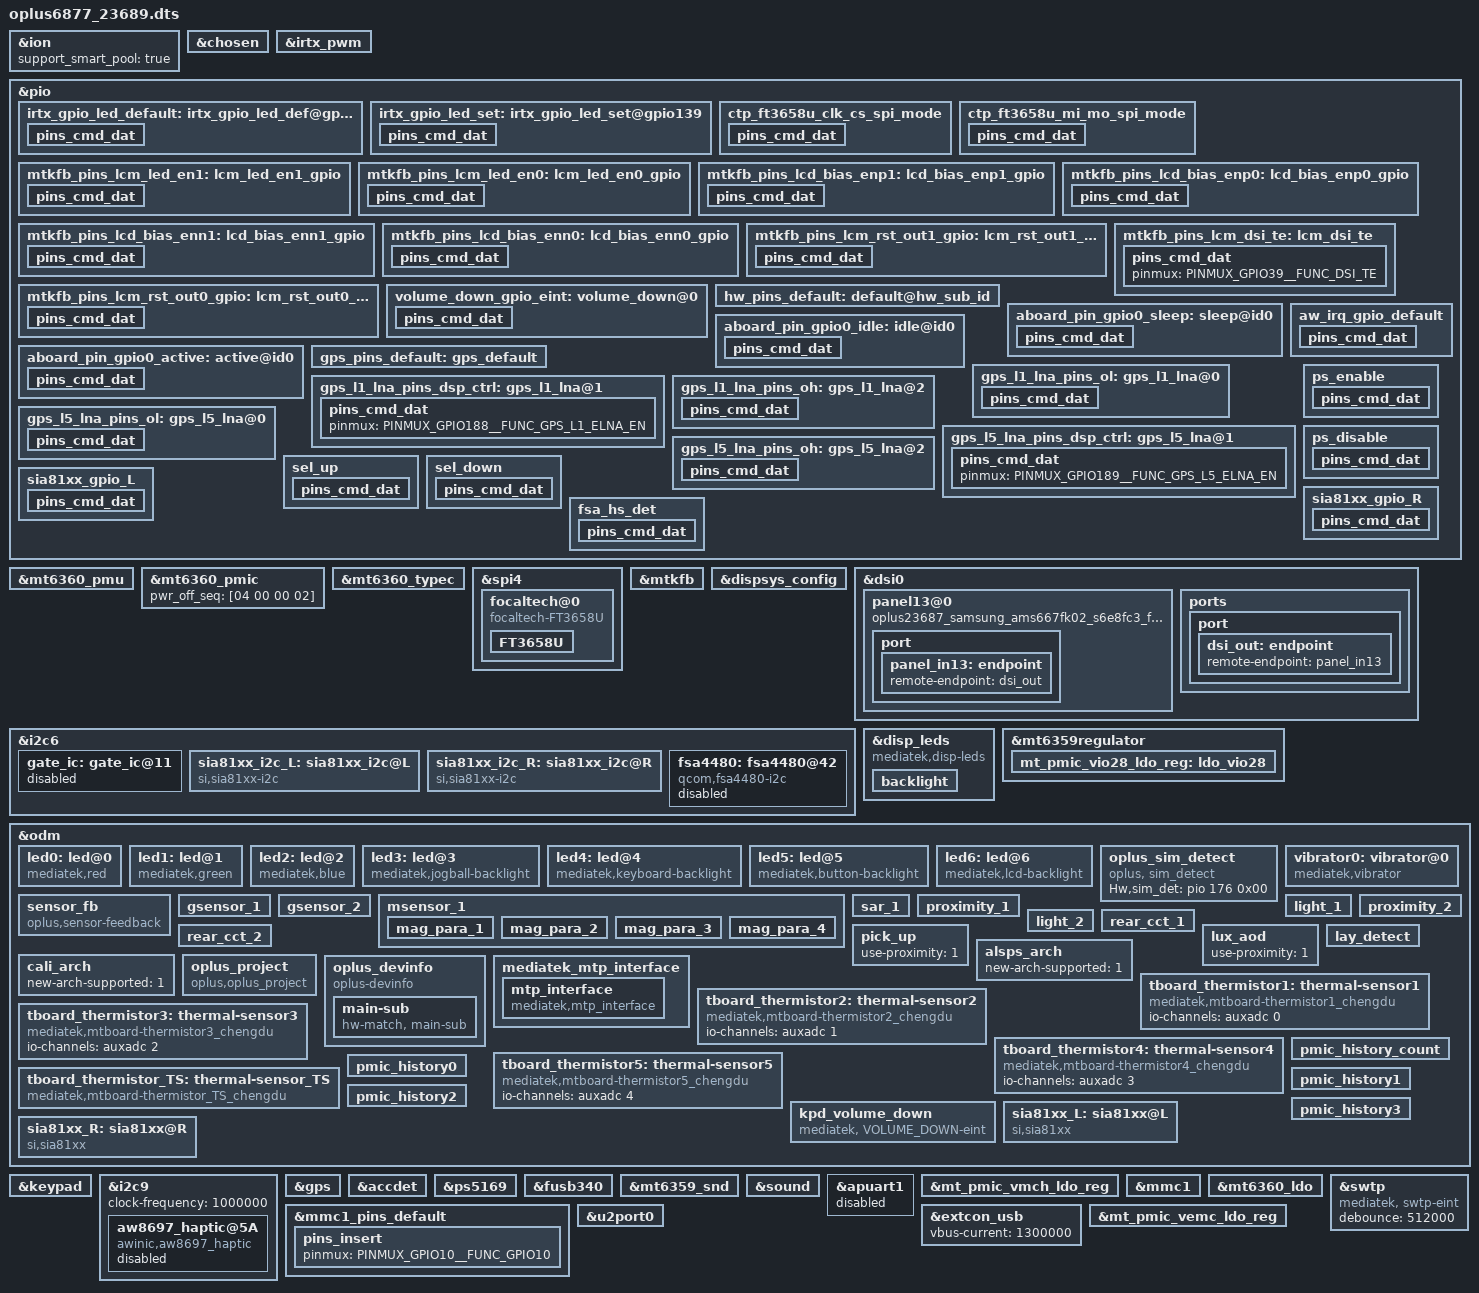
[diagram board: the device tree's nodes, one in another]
/*
 * Mediatek's mt6853 SoC device tree source
 *
 * Copyright (C) 2016 MediaTek Inc.
 *
 * This program is free software; you can redistribute it and/or modify
 * it under the terms of the GNU General Public License version 2 as
 * published by the Free Software Foundation.
 *
 * This program is distributed in the hope that it will be useful,
 * but WITHOUT ANY WARRANTY; without even the implied warranty of
 * MERCHANTABILITY or FITNESS FOR A PARTICULAR PURPOSE.
 * See http://www.gnu.org/licenses/gpl-2.0.html for more details.
 */
/dts-v1/;
/plugin/;
#include <dt-bindings/interrupt-controller/irq.h>
#include <dt-bindings/interrupt-controller/arm-gic.h>
#include <dt-bindings/pinctrl/mt6877-pinfunc.h>

/* #ifdef CONFIG_UFF_FINGERPRINT */
#include "mediatek/oplus_uff_23689.dtsi"
/* #endif CONFIG_UFF_FINGERPRINT */

&ion {
	support_smart_pool = "true";
};

/* chosen */
&chosen {
	atag,videolfb-fb_base_l = <0x7e605000>;
	atag,videolfb-fb_base_h = <0x0>;
	atag,videolfb-islcmfound = <1>;
	atag,videolfb-islcm_inited = <0>;
	atag,videolfb-fps= <6000>;
	atag,videolfb-vramSize= <0x1be0000>;
	atag,videolfb-lcmname=
		"td4330_fhdp_dsi_cmd_auo_rt4831_drv";
};

/* IRTX GPIO Start */
&irtx_pwm {
	pinctrl-names = "irtx_gpio_led_default", "irtx_gpio_led_set";
	pinctrl-0 = <&irtx_gpio_led_default>;
	pinctrl-1 = <&irtx_gpio_led_set>;
	status = "okay";
};
&pio {
	/* IRTX GPIO Settings -Start */
	/* default: GPIO0, output, high */
	irtx_gpio_led_default:irtx_gpio_led_def@gpio139 {
		pins_cmd_dat {
			pinmux = <PINMUX_GPIO139__FUNC_GPIO139>;
			slew-rate = <1>;
			bias-disable;
			output-low;
			input-schmitt-enable = <0>;
		};
	};

	irtx_gpio_led_set:irtx_gpio_led_set@gpio139 {
		pins_cmd_dat {
			pinmux = <PINMUX_GPIO139__FUNC_PWM_1>;
			slew-rate = <1>;
			output-high;
		};
	};
}; /* IRTX GPIO Settings -End */

&mt6360_pmu {
	mt6360,intr_gpio_num = <4>; /* direct defined GPIO num */
	mt6360,intr_gpio = <&pio 4 0x0>;
};

&mt6360_pmic {
	pwr_off_seq = [04 00 00 02];
};

&mt6360_typec {
	mt6360pd,intr_gpio_num = <5>; /* direct defined GPIO num */
	mt6360pd,intr_gpio = <&pio 5 0x0>;
};

&spi4 {
	status = "okay";
	#address-cells = <1>;
	#size-cells = <0>;

	pinctrl-names = "default";
	pinctrl-0 = <&ctp_ft3658u_clk_cs_spi_mode>, <&ctp_ft3658u_mi_mo_spi_mode>;
	focaltech@0{
		compatible = "focaltech-FT3658U";
		reg = <0x0>;
		chip-name = "FT3658U";
		status = "okay";
		spi-max-frequency = <6000000>;
		/* Interrupt && Irq-gpio */
		interrupt-parent = <&pio>;
		interrupts = <14 0x2002>;

		/* Power Config */

		vdd_2v8-supply  = <&mt_pmic_vtp_ldo_reg>;
		vdd_2v8_volt = <3000000>;



		/* Other HW Resource */

		irq-gpio = <&pio 14 0x2002>;
		reset-gpio = <&pio 15 0x1>;

		touchpanel,max-num-support = <10>;
		touchpanel,tx-rx-num = <16 34>;
		earsense,tx-rx-num = <17 18>;
		touchpanel,panel-coords = <8640 19200>;
		touchpanel,display-coords = <1080 2400>;
		touchpanel,touchmajor-limit = <128 216>;
		touchpanel,elimination-range = <20 200 200>;
		//touchpanel,int-mode = <1>; /*0: interrupt and disable, 1:interrupt and not disable*/
		touchpanel,msecs-to-jiffies-time = <150>;
		touchpanel,smooth-level = <0 110 115 120 140 155>;
		touchpanel,smooth-level-charging = <0 110 115 120 140 155>;
		touchpanel,sensitive-level = <0 19 16 14 13 10>;
		touchpanel,tp-index = <0>;
		touchpanel,high-frame-rate-time = <60>;

		vid_len = <2>;
		//firmware_name = "0xAB30500";
		tp_type = <8>; /* panel-SAMSUNG*/
		platform_support_project = <23613 23686 23687 23689 23707 23709>;
		platform_support_project_dir = <23687 23687 23687 23687 23687 23687>;
		platform_support_project_commandline = "default_commandline","default_commandline","default_commandline","default_commandline","default_commandline","default_commandline";

		prevention,curved_screen_V2;
		prevention,grip_disable_level = <6>;
		prevention,updelay_time_ms = <30>;
		prevention,makeup_cnt_weight = <4 1 2 2 2>;
		prevention,large_corner_range = <960 2360>;
		prevention,large_corner_judge_condition = <500 300 900 6 6>;
		prevention,trx_reject_condition = <8 7 7>;
		prevention,trx_strict_reject_condition = <7 6 6>;
		prevention,large_judge_time_ms = <500 50 30>;
		prevention,large_exit_condition = <15 12 2>;
		prevention,single_channel_width = <240 240>;
		prevention,normal_tap_condition = <10 300>;
		prevention,long_edge_condition = <230 100 180 80>;
		prevention,long_strict_edge_condition = <170 80>;
		prevention,long_fingerhold_condition = <50 6 4 4>;
		prevention,short_edge_condition = <230 100 180 80>;
		prevention,short_strict_edge_condition = <160 60>;
		prevention,large_strict_exit_condition = <5 5>;
		prevention,top_corner_config = <420 1194 360>;
		prevention,edge_swipe_config = <240 896>;

		prevention,curved_screen_V4;
		prevention,long_eliminate_point_type = <2 8640 6400 210 19200 300 1>;
		prevention,long_fingerhold_condition2 = <555 1194 0 0>;
		prevention,top_corner_config2 =<3 80 630 895 0>;
		prevention,hor_long_top_corner_config =<228 1573 0 0>;
		prevention,top_middle_config =<8640 790 790 0>;
		prevention,corner_eliminate_point_type =<0 960 1573 1>;
		prevention,finger_hold_differ_size = <1 0 240 240>;
		prevention,finger_hold_max_rx_exit_distance = <5 240 1600>;
		prevention,max_rx_exit_distance = <1 5 150 240 1600>;
		prevention,dynamic_finger_hold_exit_distance = <1 240 1600 280>;
		prevention,edge_sliding_matched_support = <1 220 3 0>;

		//grip v4.2 reclining mode
		prevention,reclining_mode_support = <1>;
		prevention,long_eliminate_point_type_recli = <2 8640 6400 210 19200 300 1>;
		prevention,finger_hold_differ_size_recli = <1 0 240 240>;
		prevention,finger_hold_max_rx_exit_distance_recli = <5 240 1600>;
		prevention,max_rx_exit_distance_recli = <1 5 150 240 1600>;
		prevention,dynamic_finger_hold_exit_distance_recli = <1 240 1600 280>;
		prevention,edge_sliding_matched_support_recli = <1 220 3 0>;
		/* SW Support Feature Control */
		//esd_handle_support;
		//register-is-16bit;
		//wireless_charger_support;
		headset_pump_support;
		fw_edge_limit_support;

		health_monitor_v2_support;
		black_gesture_support;
		charger_pump_support;
		//lcd_tp_refresh_support;
		fw_update_app_support;
		smart_gesture_support;
		game_switch_support;
		report_flow_unlock_support;
		kernel_grip_support;
		fingerprint_underscreen_support;
		pressure_report_support;
		touchpanel,single-optimized-time = <8>;
		auto_test_force_pass_support;
		snr_read_support;
		high_resolution_support;
		algorithm_support;
		screenoff_fingerprint_info_support;
		irq_need_dev_resume_ok;
		sportify_aod_gesture_support;
		black_gesture_indep_support;
		thermal_detect_support;
		exception_upload_support;
		palm_to_sleep_support;

		/*
		 *Virtual Key Config:
		 *1:touchpanel,button-type: <virtualkey_type  supportted_button-map>
		 *virtualkey_type:
		 *Type 1: using board_properties
		 *Type 2: using same IC (button zone&& touch zone are seprate)
		 *Type 3: using diffrent IC (button zone&& touch zone are seprate)
		 *Type 4: No need of virtual key process
		 *supportted_button-map:select|menu|home|back
		 *
		 *2:touchpanel,button-map
		 *type (X1,Y1)(X2,Y2)(X3,Y3)(Width_X,Hight_Y)--Only when button-type is 0
		 */
		touchpanel,button-type = <4>;
		touchpanel.button-TRx = <0 0>;

		FT3658U {
			switch_report_rate;
			report_rate_default = <60>;
			report_rate_game_value = <0x02>;
		};
	};
};

&pio {
	ctp_ft3658u_clk_cs_spi_mode: ctp_ft3658u_clk_cs_spi_mode{
		pins_cmd_dat {
			pinmux = <PINMUX_GPIO64__FUNC_SPI4_CLK>,
				<PINMUX_GPIO65__FUNC_SPI4_CSB>;
			mediatek,drive-strength-adv = <0>;/*EH[2:0]*/
			drive-strength = <2>;
		};
	};
	ctp_ft3658u_mi_mo_spi_mode: ctp_ft3658u_mi_mo_spi_mode {
		pins_cmd_dat {
			pinmux = <PINMUX_GPIO12__FUNC_SPI4_MI>,
				<PINMUX_GPIO13__FUNC_SPI4_MO>;
			drive-strength = <2>;
		};
	};

};
/*touch end*/

&pio {
	mtkfb_pins_lcm_led_en1: lcm_led_en1_gpio {
		pins_cmd_dat {
			pinmux = <PINMUX_GPIO107__FUNC_GPIO107>;
			slew-rate = <1>;
			output-high;
		};
	};

	mtkfb_pins_lcm_led_en0: lcm_led_en0_gpio {
		pins_cmd_dat {
			pinmux = <PINMUX_GPIO107__FUNC_GPIO107>;
			slew-rate = <1>;
			output-low;
		};
	};

	mtkfb_pins_lcd_bias_enp1: lcd_bias_enp1_gpio {
		pins_cmd_dat {
			pinmux = <PINMUX_GPIO108__FUNC_GPIO108>;
			slew-rate = <1>;
			output-high;
		};
	};

	mtkfb_pins_lcd_bias_enp0: lcd_bias_enp0_gpio {
		pins_cmd_dat {
			pinmux = <PINMUX_GPIO108__FUNC_GPIO108>;
			slew-rate = <1>;
			output-low;
		};
	};

	mtkfb_pins_lcd_bias_enn1: lcd_bias_enn1_gpio {
		pins_cmd_dat {
			pinmux = <PINMUX_GPIO111__FUNC_GPIO111>;
			slew-rate = <1>;
			output-high;
		};
	};

	mtkfb_pins_lcd_bias_enn0: lcd_bias_enn0_gpio {
		pins_cmd_dat {
			pinmux = <PINMUX_GPIO111__FUNC_GPIO111>;
			slew-rate = <1>;
			output-low;
		};
	};

	mtkfb_pins_lcm_rst_out1_gpio: lcm_rst_out1_gpio {
		pins_cmd_dat {
			pinmux = <PINMUX_GPIO40__FUNC_GPIO40>;
			slew-rate = <1>;
			output-high;
		};
	};

	mtkfb_pins_lcm_rst_out0_gpio: lcm_rst_out0_gpio {
		pins_cmd_dat {
			pinmux = <PINMUX_GPIO40__FUNC_GPIO40>;
			slew-rate = <1>;
			output-low;
		};
	};
	mtkfb_pins_lcm_dsi_te: lcm_dsi_te {
		pins_cmd_dat {
			pinmux = <PINMUX_GPIO39__FUNC_DSI_TE>;
		};
	};
};

&mtkfb {
	pinctrl-names = "lcm_led_en1_gpio", "lcm_led_en0_gpio",
		"lcd_bias_enp1_gpio", "lcd_bias_enp0_gpio",
		"lcd_bias_enn1_gpio", "lcd_bias_enn0_gpio",
		"lcm_rst_out1_gpio", "lcm_rst_out0_gpio",
		"mode_te_te";
	pinctrl-0 = <&mtkfb_pins_lcm_led_en1>;
	pinctrl-1 = <&mtkfb_pins_lcm_led_en0>;
	pinctrl-2 = <&mtkfb_pins_lcd_bias_enp1>;
	pinctrl-3 = <&mtkfb_pins_lcd_bias_enp0>;
	pinctrl-4 = <&mtkfb_pins_lcd_bias_enn1>;
	pinctrl-5 = <&mtkfb_pins_lcd_bias_enn0>;
	pinctrl-6 = <&mtkfb_pins_lcm_rst_out1_gpio>;
	pinctrl-7 = <&mtkfb_pins_lcm_rst_out0_gpio>;
	pinctrl-8 = <&mtkfb_pins_lcm_dsi_te>;
	status = "okay";
};
&dispsys_config {
	pinctrl-names =
		"lcm_rst_out1_gpio", "lcm_rst_out0_gpio",
		"mode_te_te";
	pinctrl-0 = <&mtkfb_pins_lcm_rst_out1_gpio>;
	pinctrl-1 = <&mtkfb_pins_lcm_rst_out0_gpio>;
	pinctrl-2 = <&mtkfb_pins_lcm_dsi_te>;
	status = "okay";

	helper-value = <0>, /*MTK_DRM_OPT_STAGE*/
		<1>, /*MTK_DRM_OPT_USE_CMDQ*/
		<1>, /*MTK_DRM_OPT_USE_M4U*/
		<0>, /*MTK_DRM_OPT_SODI_SUPPORT*/
		<1>, /*MTK_DRM_OPT_IDLE_MGR*/
		<0>, /*MTK_DRM_OPT_IDLEMGR_SWTCH_DECOUPLE*/
		<0>, /*MTK_DRM_OPT_IDLEMGR_BY_REPAINT*/
		<0>, /*MTK_DRM_OPT_IDLEMGR_ENTER_ULPS*/
		<0>, /*MTK_DRM_OPT_IDLEMGR_KEEP_LP11*/
		<0>, /*MTK_DRM_OPT_DYNAMIC_RDMA_GOLDEN_SETTING*/
		<1>, /*MTK_DRM_OPT_IDLEMGR_DISABLE_ROUTINE_IRQ*/
		<0>, /*MTK_DRM_OPT_MET_LOG*/
		<1>, /*MTK_DRM_OPT_USE_PQ*/
		<1>, /*MTK_DRM_OPT_ESD_CHECK_RECOVERY*/
		<1>, /*MTK_DRM_OPT_ESD_CHECK_SWITCH*/
		<1>, /*MTK_DRM_OPT_PRESENT_FENCE*/
		<1>, /*MTK_DRM_OPT_RDMA_UNDERFLOW_AEE*/
		<1>, /*MTK_DRM_OPT_DSI_UNDERRUN_AEE*/
		<1>, /*MTK_DRM_OPT_HRT*/
		<1>, /*MTK_DRM_OPT_HRT_MODE*/
		<0>, /*MTK_DRM_OPT_DELAYED_TRIGGER*/
		<1>, /*MTK_DRM_OPT_OVL_EXT_LAYER*/
		<0>, /*MTK_DRM_OPT_AOD*/
		<1>, /*MTK_DRM_OPT_RPO*/
		<0>, /*MTK_DRM_OPT_DUAL_PIPE*/
		<0>, /*MTK_DRM_OPT_DC_BY_HRT*/
		<0>, /*MTK_DRM_OPT_OVL_WCG*/
		<0>, /*MTK_DRM_OPT_OVL_SBCH*/
		<1>, /*MTK_DRM_OPT_COMMIT_NO_WAIT_VBLANK*/
		<0>, /*MTK_DRM_OPT_MET*/
		<0>, /*MTK_DRM_OPT_REG_PARSER_RAW_DUMP*/
		<0>, /*MTK_DRM_OPT_VP_PQ*/
		<0>, /*MTK_DRM_OPT_GAME_PQ*/
		<0>, /*MTK_DRM_OPT_MMPATH*/
		<1>, /*MTK_DRM_OPT_HBM*/
		<0>, /*MTK_DRM_OPT_VDS_PATH_SWITCH*/
		<0>, /*MTK_DRM_OPT_LAYER_REC*/
		<0>, /*MTK_DRM_OPT_CLEAR_LAYER*/
		<1>, /*MTK_DRM_OPT_LFR*/
		<1>; /*MTK_DRM_OPT_DYN_MIPI_CHANGE*/
};

&dsi0 {
	status = "okay";
	#address-cells = <1>;
	#size-cells = <0>;
	panel13@0 {
		compatible = "oplus23687_samsung_ams667fk02_s6e8fc3_fhdp_dsi_vdo";
		reg = <0>;
		vddr-enable-gpios = <&pio 107 0>;
		vci-enable-gpios = <&pio 105 0>;
		reset-gpios = <&pio 40 0>;
		pinctrl-names = "default";
		port {
			panel_in13: endpoint {
				remote-endpoint = <&dsi_out>;
			};
		};
	};
	ports {
		port {
			dsi_out: endpoint {
				remote-endpoint = <&panel_in13>;
			};
		};
	};
};

&i2c6 {
	gate_ic: gate_ic@11 {
		status = "disable";
	};
};

&disp_leds {
	compatible = "mediatek,disp-leds";
	backlight {
		label = "lcd-backlight";
		max-brightness = <4095>;
		led-bits = <12>;
		trans-bits = <12>;
		// support_silky_brightness = <1>;
		default-state = "on";
	};
};

&mt6359regulator {
	mt_pmic_vio28_ldo_reg: ldo_vio28 {
		regulator-name = "vio28";
		regulator-min-microvolt = <3300000>;
		regulator-max-microvolt = <3300000>;
		regulator-enable-ramp-delay = <1920>;
		};
};

&odm {
	led0:led@0 {
		compatible = "mediatek,red";
		led_mode = <0>;
		data = <1>;
		pwm_config = <0 0 0 0 0>;
	};
	led1:led@1 {
		compatible = "mediatek,green";
		led_mode = <0>;
		data = <1>;
		pwm_config = <0 0 0 0 0>;
	};
	led2:led@2 {
		compatible = "mediatek,blue";
		led_mode = <0>;
		data = <1>;
		pwm_config = <0 0 0 0 0>;
	};
	led3:led@3 {
		compatible = "mediatek,jogball-backlight";
		led_mode = <0>;
		data = <1>;
		pwm_config = <0 0 0 0 0>;
	};
	led4:led@4 {
		compatible = "mediatek,keyboard-backlight";
		led_mode = <0>;
		data = <1>;
		pwm_config = <0 0 0 0 0>;
	};
	led5:led@5 {
		compatible = "mediatek,button-backlight";
		led_mode = <0>;
		data = <1>;
		pwm_config = <0 0 0 0 0>;
	};
	led6:led@6 {
		compatible = "mediatek,lcd-backlight";
		led_mode = <4>;
		data = <1>;
		pwm_config = <0 1 0 0 0>;
	};
    oplus_sim_detect {
	    compatible = "oplus, sim_detect";
	    Hw,sim_det = <&pio 176 0x00>;
    };
    vibrator0:vibrator@0 {
	    compatible = "mediatek,vibrator";
	    vib_timer = <35>;
	    vib_limit = <9>;
	    vib_vol= <9>;
    };
/* sensor start */
	/*
	enum {
		LIS3DH,
		LSM6DS3,
		BMI160,
		LIS2HH12,
		LSM6DSM,
		BMI2XY,
		LSM6DSO,
		BMA4XY,
		SC7A20,
		ICM4X6XX,
	};
	*/
    sensor_fb: sensor_fb {
            compatible = "oplus,sensor-feedback";
    };

	gsensor_1: gsensor_1 {
		status = "okay";
		sensor_name = <7>;//ICM4X6XX
		device_name = "icm4x6xx";
		i2c_num = <2>;
		i2c_addr = <0>;
		direction = <2>;
		eint_num = <1>;
		step_count_7_en = <1>;
		config_miso = <1>;
		correct_y_bias = <1>;
		gyro_cali_version= <2>;
		gyro_cali_range = <350>; //0.35 rad/s
		acc_cali_range= <300 300 300>; //250mg
	};
	gsensor_2: gsensor_2 {
		status = "okay";
		sensor_name = <10>;//BMI3XY
		device_name = "bmi3xy";
		i2c_num = <2>;
		i2c_addr = <0>;
		direction = <1>;
		eint_num = <1>;
		gyro_cali_version= <2>;
		gyro_cali_range = <350>; //0.35 rad/s
		acc_cali_range= <300 300 300>; //250mg
	};
	/*
	enum {
		AKM09911,
		MMC3530,
		MMC5603,
		MXG4300,
	};
	*/
	msensor_1: msensor_1 {
		status = "okay";
		sensor_name = <2>;//MMC5603
		i2c_num = <0>;
		i2c_addr = <48>;
		direction = <3>;
		eint_num = <0>;
		para_num = <4>;
		libname = "mmc";
		mag_para_1 {
			match_projects = <23613>;
			soft-mag-parameter = <9969 0 755 0 36 0 157 1 8220 0 124 0 449 0 24 0 10391 0>;
		};
		mag_para_2 {
			match_projects = <23686>;
			soft-mag-parameter = <9995 0 224 0 119 1 686 1 8070 0 198 0 175 0 387 0 10181 0>;
		};
		mag_para_3 {
			match_projects = <23687>;
			soft-mag-parameter = <9959 0 875 0 186 0 269 1 8184 0 257 0 89 0 120 0 10452 0>;
		};
		mag_para_4 {
			match_projects = <23689>;
			soft-mag-parameter = <9997 0 12 1 228 0 806 0 9125 0 82 0 196 1 333 0 10375 0>;
		};
	};
	/*
	enum {
		SX933x
	};
	*/
	sar_1: sar_1 {
		status = "okay";
		sensor_name = <0>;//SX933x
		i2c_num = <0>;
		i2c_addr = <40>;
		direction = <4>;
		eint_num = <13>;
		channel_num = <2>;
		channel_0_min = <0>;
		channel_0_max = <70000>;
		channel_1_min = <0>;
		channel_1_max = <70000>;
		channel_2_min = <0>;
		channel_2_max = <70000>;
		channel_3_min = <0>;
		channel_3_max = <70000>;
		reg_table_num = <3>;
	};
	/*
	enum {
		TMD2725,
		APSD9922,
		STK3335,
		STK3331,
		STK2232,
		TCS3701,
		STK32600,
	};
	*/
	proximity_1: proximity_1 {
		status = "okay";
		sensor_name = <6>;//STK32600
		i2c_num = <0>;
		i2c_addr = <72>;
		direction = <4>;
		eint_num = <2>;
		low_step = <300>;
		high_step = <400>;
		low_limit = <400>;
		high_limit = <600>;
		dirty_low_step = <300>;
		dirty_high_step = <400>;
		ps_dirty_limit = <1800>;
		ps_ir_limit = <2000>;
		ps_adjust_min = <0>;
		ps_adjust_max = <1850>;
		sampling_count = <5>;
		step_max = <400>;
		step_min = <100>;
		step_div = <2000>;
		anti_shake_delta = <70>;
		dynamic_cali_max = <5000>;
		raw2offset_radio = <1000>;
		offset_max = <60000>;
		offset_range_min = <0>;
		offset_range_max = <65535>;
		force_cali_limit = <2000>;
		cali_jitter_limit = <30>;
		cal_offset_margin = <3000>;
		sensor-reg = <0x03 0x28>;
		is_use_force_cali = <1>;
	};
	light_1: light_1 {
		status = "okay";
		sensor_name = <6>;//STK32600
		i2c_num = <0>;
		i2c_addr = <72>;
		direction = <4>;
		eint_num = <2>;
		als_buffer_length =<8>;
		als_ratio = <110>;
		als_type = <2>;//<1-normal;2-under screen;3-normal needed compensation>
		device_name = "stk32600";
		use_als_c2 = <1>;
	};
	proximity_2: proximity_2 {
		status = "okay";
		sensor_name = <10>;//STK33C01
		device_name = "stk33c01";
		i2c_num = <0>;
		i2c_addr = <72>;
		direction = <4>;
		eint_num = <2>;
		low_step = <300>;
		high_step = <400>;
		low_limit = <400>;
		high_limit = <600>;
		dirty_low_step = <300>;
		dirty_high_step = <400>;
		ps_dirty_limit = <1800>;
		ps_ir_limit = <2000>;
		ps_adjust_min = <0>;
		ps_adjust_max = <1850>;
		sampling_count = <5>;
		step_max = <400>;
		step_min = <100>;
		step_div = <2000>;
		anti_shake_delta = <70>;
		dynamic_cali_max = <5000>;
		raw2offset_radio = <1000>;
		offset_max = <60000>;
		offset_range_min = <0>;
		offset_range_max = <65534>;
		force_cali_limit = <2000>;
		cali_jitter_limit = <30>;
		cal_offset_margin = <3000>;
		is_use_force_cali = <1>;
		parameter-number = <8>;
		sensor-reg = <0x01 0x44
				0x03 0x28
				0x05 0x3F
				0xDB 0x00>; //override special reg
	};
	light_2: light_2 {
		status = "okay";
		sensor_name = <10>;//STK33C01
		i2c_num = <0>;
		i2c_addr = <72>;
		direction = <4>;
		eint_num = <2>;
		als_buffer_length =<8>;
		als_ratio = <110>;
		als_coef_ratio = <88>;
		als_type = <2>;//<1-normal;2-under screen;3-normal needed compensation>
		device_name = "stk33c01";

	};
	/*
	enum {
		STK37600,
		MN29005,
		TCS3408,
	};
	*/
	rear_cct_1: rear_cct_1 {
		status = "okay";
		sensor_name = <0>;//STK37600
		i2c_num = <1>;
		i2c_addr = <0x48>;
		direction = <0>;
		eint_num = <10>;
		available_sensor = <7>; // bit 0: rear als, bit 1: rear cct, bit 2: rear flicker
		gold_rear_cct_3k = <11083 14060 1700 488 64 42136>; // 3000k gold parameter
		gold_rear_cct_6k = <8488 13068 3928 372 64 42964>;  // 3000k gold parameter
		device_name = "stk37600";
		cct_coef_Lir = <9116000 0 259000 0 1711000 1 7351000 0 12875000 0
				1686000 0 3545000 0 6606000 0 51505000 0 3221000 1
				2492000 1 2826000 1>;
		cct_coef_Hir = <178000 1 14775000 1 36798000 1 13552000 0 24758000 0
				31340000 0 3274000 1 7368000 1 19817000 0 161000 1
				23000 0 392000 0>;
	};
	rear_cct_2: rear_cct_2 {
		status = "okay";
		sensor_name = <3>;//SIP1221LR1N
		i2c_num = <1>;
		i2c_addr = <0x59>;
		direction = <0>;
		eint_num = <10>;
		available_sensor = <4>; // bit 0: rear als, bit 1: rear cct, bit 2: rear flicker
		device_name = "sip1221lr1n";
	};
	pick_up: pick_up {
		status = "okay";
		use-proximity = <1>;
	};
	lux_aod: lux_aod {
		status = "okay";
		use-proximity = <1>;
	};
	alsps_arch: alsps_arch {
		status = "okay";
		new-arch-supported = <1>;
	};
	cali_arch: cali_arch {
		status = "okay";
		new-arch-supported = <1>;
	};
	lay_detect: lay_detect{
		status = "okay";
		max_angel = <90>;
		min_angel = <30>;
		lay_in_time = <10>;
		lay_out_time = <3>;
	};
/* sensor end */

/* OPLUS_BUG_STABILITY oplus project start */
	oplus_project:oplus_project {
		compatible = "oplus,oplus_project";
	};
	oplus_devinfo:oplus_devinfo {
		compatible = "oplus-devinfo";

		pinctrl-names = "default", "aboard_gpio0_sleep", "aboard_gpio0_active", "aboard_gpio0_idle";
		pinctrl-0 = <&hw_pins_default>;
		pinctrl-1 = <&aboard_pin_gpio0_sleep>;
		pinctrl-2 = <&aboard_pin_gpio0_active>;
		pinctrl-3 = <&aboard_pin_gpio0_idle>;
		main-sub {
			use_tristate_gpio;
            compatible = "hw-match, main-sub";
			aboard-gpio0 = <&pio 103 0x00>;
			aboard-patterns = <2 1 0 2>;
			/*main board*/
			match-projects = <23613 23686 23687 23689>;
        };
	};
/* OPLUS_BUG_STABILITY oplus project end */

	mediatek_mtp_interface:mediatek_mtp_interface {
		mtp_interface {
			compatible = "mediatek,mtp_interface";
			InterfaceClass = <255>;
			InterfaceSubClass = <255>;
			InterfaceProtocol = <0>;
	};
};


/*	tboard_thermistor5: thermal-sensor5 {
		compatible = "mediatek,mtboard-thermistor5";
		io-channels = <&auxadc 4>;
		io-channel-names = "thermistor-ch4";
	};
*/
/* 20221216, add for AP, 4G pA, 5G PA, charger, sub_bat, flashlight ntc*/
	tboard_thermistor1: thermal-sensor1 {
		compatible = "mediatek,mtboard-thermistor1_chengdu";
		io-channels = <&auxadc 0>;
		io-channel-names = "thermistor-ch0";
	};
	tboard_thermistor2: thermal-sensor2 {
		compatible = "mediatek,mtboard-thermistor2_chengdu";
		io-channels = <&auxadc 1>;
		io-channel-names = "thermistor-ch1";
	};
	tboard_thermistor3: thermal-sensor3 {
		compatible = "mediatek,mtboard-thermistor3_chengdu";
		io-channels = <&auxadc 2>;
		io-channel-names = "thermistor-ch2";
	};
	tboard_thermistor4: thermal-sensor4 {
		compatible = "mediatek,mtboard-thermistor4_chengdu";
		io-channels = <&auxadc 3>;
		io-channel-names = "thermistor-ch3";
	};
	tboard_thermistor5: thermal-sensor5 {
		compatible = "mediatek,mtboard-thermistor5_chengdu";
		io-channels = <&auxadc 4>;
		io-channel-names = "thermistor-ch4";
	};
	tboard_thermistor_TS: thermal-sensor_TS {
		compatible = "mediatek,mtboard-thermistor_TS_chengdu";
	};

	kpd_volume_down:kpd_volume_down {
		compatible = "mediatek, VOLUME_DOWN-eint";
		interrupt-parent = <&pio>;
		interrupts = <7 IRQ_TYPE_EDGE_FALLING 7 0>;
		debounce = <32000>;
		status = "okay";
	};

	pmic_history_count:pmic_history_count {
	};
	pmic_history0:pmic_history0 {
	};
	pmic_history1:pmic_history1 {
	};
	pmic_history2:pmic_history2 {
	};
	pmic_history3:pmic_history3 {
	};

};

&keypad {
	keypad,volume-down	= <&pio 7 0x00>;
	pinctrl-names = "volume_down_as_int";
	pinctrl-0 = <&volume_down_gpio_eint>;
	status = "okay";
};

&pio {
	volume_down_gpio_eint:volume_down@0{
		pins_cmd_dat {
			pinmux = <PINMUX_GPIO7__FUNC_GPIO7>;
			slew-rate = <0>;  /*direction 0:in, 1:out*/
			input-enable;
		};
	};
};

&pio {
        hw_pins_default:default@hw_sub_id {
        };

        aboard_pin_gpio0_sleep:sleep@id0 {
                pins_cmd_dat {
                        pinmux = <PINMUX_GPIO103__FUNC_GPIO103>;
                        slew-rate = <0>;
                        bias-pull-down;
                        input-enable;
                };
        };

        aboard_pin_gpio0_active:active@id0 {
                pins_cmd_dat {
                        pinmux = <PINMUX_GPIO103__FUNC_GPIO103>;
                        slew-rate = <0>;
                        bias-pull-up;
                        input-enable;
                };
        };

        aboard_pin_gpio0_idle:idle@id0 {
                pins_cmd_dat {
                        pinmux = <PINMUX_GPIO103__FUNC_GPIO103>;
                        slew-rate = <0>;
                        bias-disable;
                        input-enable;
                };
        };
};

&i2c9 {
    status = "okay";
	clock-frequency = <1000000>;

	/* AWINIC AW8697 Haptic */
	aw8697_haptic@5A {
		status = "disable";
		compatible = "awinic,aw8697_haptic";
		reg = <0x5A>;
		reset-gpio = <&pio 26 0x00>;
		irq-gpio = <&pio 30 0x00>;
		qcom,device_id = <815>;//aw86927
		audio_delay = <60>;
		qcom,aw86927_boost_voltage = /bits/ 8 <0x52>;

		pinctrl-names = "default";
		pinctrl-0 = <&aw_irq_gpio_default>;
	};
};

&pio{
	aw_irq_gpio_default: aw_irq_gpio_default {		//check
		pins_cmd_dat {
			pinmux = <PINMUX_GPIO30__FUNC_GPIO30>;
			input-enable;
			bias-pull-up = <MTK_PUPD_SET_R1R0_10>;
		};
	};

};

/* GPS GPIO standardization start */
&pio {
	gps_pins_default: gps_default {
	};
	gps_l1_lna_pins_ol: gps_l1_lna@0 {
		pins_cmd_dat {
			pinmux = <PINMUX_GPIO188__FUNC_GPIO188>;
			output-low;
		};
	};
	gps_l1_lna_pins_dsp_ctrl: gps_l1_lna@1 {
		pins_cmd_dat {
			pinmux = <PINMUX_GPIO188__FUNC_GPS_L1_ELNA_EN>;
		};
	};
	gps_l1_lna_pins_oh: gps_l1_lna@2 {
		pins_cmd_dat {
			pinmux = <PINMUX_GPIO188__FUNC_GPIO188>;
			output-high;
		};
	};
	gps_l5_lna_pins_ol: gps_l5_lna@0 {
		pins_cmd_dat {
			pinmux = <PINMUX_GPIO189__FUNC_GPIO189>;
			output-low;
		};
	};
	gps_l5_lna_pins_dsp_ctrl: gps_l5_lna@1 {
		pins_cmd_dat {
			pinmux = <PINMUX_GPIO189__FUNC_GPS_L5_ELNA_EN>;
		};
	};
	gps_l5_lna_pins_oh: gps_l5_lna@2 {
		pins_cmd_dat {
			pinmux = <PINMUX_GPIO189__FUNC_GPIO189>;
			output-high;
		};
	};
};
&gps {
	pinctrl-names = "default",
		"gps_l1_lna_disable",
		"gps_l1_lna_dsp_ctrl",
		"gps_l1_lna_enable";
		//"gps_l5_lna_disable",
		//"gps_l5_lna_dsp_ctrl",
		//"gps_l5_lna_enable";
	pinctrl-0 = <&gps_pins_default>;
	pinctrl-1 = <&gps_l1_lna_pins_ol>;
	pinctrl-2 = <&gps_l1_lna_pins_dsp_ctrl>;
	pinctrl-3 = <&gps_l1_lna_pins_oh>;
	//pinctrl-4 = <&gps_l5_lna_pins_ol>;
	//pinctrl-5 = <&gps_l5_lna_pins_dsp_ctrl>;
	//pinctrl-6 = <&gps_l5_lna_pins_oh>;
	status = "okay";
};
/* GPS GPIO standardization end */

&accdet {
	/* accdet micbias voltage: 0x09:2.85v 0x08:2.8v 0x07,
	 * 2.7v;0x05,2.5v;0x02,1.9v
	 */
	accdet-mic-vol = <7>;
	/* accdet pwm_width, pwm_thresh, fall_delay, rise_delay
	 * debounce0, debounce1, debounce3, debounce4
	 * eint pwm_width, eint pwm_thresh
	 * eint deb(debounce0, debounce1, debounce2, debounce3), inv_debounce
	 */
	//#ifdef OPLUS_ARCH_EXTENDS
	/* Modify for bug 136344 */
	headset-mode-setting = <0x500 0x500 1 0x1f0
				0x1325 0x800 0x3D4 0x44
				0x0 0x7
				0x5 0x9 0x9 0xd 0xe>;
	//#else /* OPLUS_ARCH_EXTENDS */
	/*headset-mode-setting = <0x500 0x500 1 0x1f0
	*                      0x800 0x800 0x20 0x44
	*                      0x4 0x1
	*                      0x5 0x3 0x3 0x5 0xe>;
	*/
	//#endif /* OPLUS_ARCH_EXTENDS */
	accdet-plugout-debounce = <1>;
	/*1:ACC mode, 2:low cost without in bias, 6:low cost with in bias*/
	accdet-mic-mode = <2>;
	/*0--MD_MAX--UP_MAX--DW_MAX*/
	headset-three-key-threshold = <0 82 170 306>;
	//#else
	//headset-three-key-threshold = <0 80 220 400>;
	//#endif
	headset-three-key-threshold-CDD = <0 121 192 600>;
	/*0--MD_MAX--VOICE_MAX--UP_MAX--DW_MAX*/
	headset-four-key-threshold = <0 58 121 192 400>;

//#ifdef OPLUS_ARCH_EXTENDS
	/* moisture HW mode config start. Enable moisture detection or not
	 * default use HW mode for moisture detection
	 */
	moisture_detect_enable = <1>;
//#endif /* OPLUS_ARCH_EXTENDS */
	/* select VTH to 2v and 500k, use internal resitance */
	eint_use_ext_res = <0>;
//#ifdef OPLUS_ARCH_EXTENDS
	/* enable eint detection mode, if moisture detection enable
	 * eint_detect_mode = moisture_detect_mode;otherwise, select
	 * eint_detect_mode = 4 as DEFAULT
	 */
	eint_detect_mode = <5>;
	/* enable moisture detection mode, if moisture detection enable
	 * eint_detect_mode = moisture_detect_mode
	 */
	moisture_detect_mode = <5>;
	/* select 0: 2.8V; 1: 2.4V; 2: 2V; 3: VTH=MVTH(VTH2) */
	moisture_comp_vth = <2>;
	/* vref2 voltage for different water impedance */
//#ifdef OPLUS_ARCH_EXTENDS
	moisture_comp_vref2 = <2>;
//
	/* vref2 voltage for different water impedance */
//	moisture_comp_vref2 = <0>;
//#endif
	/* moisture HW mode config end */

	/* moisture SW mode config start, use external resister or not.
	 * DEFAULT NOT NEED
	 */
	moisture_use_ext_res = <0>;
	/* moisture external resister ohm, SW mode by auxadc */
	moisture-external-r = <2000000>;
	/* moisture internal resister ohm, SW mode by auxadc */
	moisture-internal-r = <47000>;
	/* moisture of water resister ohm, SW mode by auxadc*/
	moisture-water-r = <10000>;
	/* moisture SW mode config end */
//#endif /* OPLUS_ARCH_EXTENDS */
	status = "okay";
};

&ps5169{
	pinctrl-names = "enable", "disable";
	pinctrl-0 = <&ps_enable>;
	pinctrl-1 = <&ps_disable>;
	status = "okay";
};

&fusb340 {
	pinctrl-names = "sel_up", "sel_down";
	pinctrl-0 = <&sel_up>;
	pinctrl-1 = <&sel_down>;
	status = "okay";
};

&pio {
	ps_enable: ps_enable {
		pins_cmd_dat {
			pinmux = <PINMUX_GPIO121__FUNC_GPIO121>;
			output-high;
		};
	};

	ps_disable: ps_disable {
		pins_cmd_dat {
			pinmux = <PINMUX_GPIO121__FUNC_GPIO121>;
			output-low;
		};
	};

	sel_up: sel_up {
		pins_cmd_dat {
			pinmux = <PINMUX_GPIO6__FUNC_GPIO6>;
			output-low;
		};
	};

	sel_down: sel_down {
		pins_cmd_dat {
			pinmux = <PINMUX_GPIO6__FUNC_GPIO6>;
			output-high;
		};
	};
};

&pio {
	sia81xx_gpio_L: sia81xx_gpio_L {
		pins_cmd_dat {
			pinmux = <PINMUX_GPIO31__FUNC_GPIO31>;
			slew-rate = <1>;
			bias-disable;
		};
	};

	sia81xx_gpio_R: sia81xx_gpio_R {
		pins_cmd_dat {
			pinmux = <PINMUX_GPIO24__FUNC_GPIO24>;
			slew-rate = <1>;
			bias-disable;
		};
	};
};

&mt6359_snd {
	mediatek,micbias0-mv = <2700>;
	mediatek,micbias2-mv = <2700>;
};

&odm {
	sia81xx_L: sia81xx@L {
		compatible = "si,sia81xx";
		si,sia81xx_type = "sia8159";
		si,sia81xx_reset = <&pio 31 0>;
		si,sia81xx_owi = <&pio 31 0>;
		pinctrl-names = "sia81xx_gpio";
		pinctrl-0 = <&sia81xx_gpio_L>;
		si,sia81xx_disable_pin = <1>;
		/* the same value share a same task
		* valid value range : 0 ~ 7 */
		timer_task_hdl = <0>;
		channel_num = <0>;
		owi_mode = <6>;
		en_x_filter = <0>;
		en_dynamic_updata_vdd = <0>;
		en_dynamic_updata_pvdd = <0>;
		dynamic_updata_vdd_port = <0x2>;
	};
	sia81xx_R: sia81xx@R {
		compatible = "si,sia81xx";
		si,sia81xx_type = "sia8159";
		si,sia81xx_reset = <&pio 24 0>;
		si,sia81xx_owi = <&pio 24 0>;
		pinctrl-names = "sia81xx_gpio";
		pinctrl-0 = <&sia81xx_gpio_R>;
		si,sia81xx_disable_pin = <1>;
		/* the same value share a same task
		* valid value range : 0 ~ 7 */
		timer_task_hdl = <0>;
		channel_num = <1>;
		owi_mode = <6>;
		en_x_filter = <0>;
		en_dynamic_updata_vdd = <0>;
		en_dynamic_updata_pvdd = <0>;
		dynamic_updata_vdd_port = <0x2>;
	};
};


&sound {
	si,sia81xx-max-num = <2>;
	si,sia81xx-aux-devs = <&sia81xx_L>, <&sia81xx_R>;
	si,sia81xx-aux-devs-prefix = "SpkrLeft", "SpkrRight";
};

//#ifdef OPLUS_TFA98XX
&i2c6 {
	#address-cells = <1>;
	#size-cells = <0>;
	clock-frequency = <400000>;
	mediatek,use-open-drain;

	sia81xx_i2c_L: sia81xx_i2c@L {
		compatible = "si,sia81xx-i2c";
		reg = <0x28>;
		si,sia81xx-dev = <&sia81xx_L>;
	};

	sia81xx_i2c_R: sia81xx_i2c@R {
		compatible = "si,sia81xx-i2c";
		reg = <0x29>;
		si,sia81xx-dev = <&sia81xx_R>;
	};
};


&pio {
	fsa_hs_det: fsa_hs_det {
		pins_cmd_dat {
			pinmux = <PINMUX_GPIO166__FUNC_GPIO166>;
			slew-rate = <1>;  /*direction 0:in, 1:out*/
			output-high;
		};
	};
};

&i2c6 {
	fsa4480: fsa4480@42 {
		compatible = "qcom,fsa4480-i2c";
		reg = <0x42>;
		pinctrl-names = "default";
		pinctrl-0 = <&fsa_hs_det>;
		fsa4480,hs-det-gpio = <&pio 166 0>;
		status = "disabled";
	};
};

&apuart1 {
	status = "disabled";
};

&mt_pmic_vmch_ldo_reg {
    regulator-min-microvolt = <2700000>;
    regulator-max-microvolt = <3600000>;
};

&mmc1 {
     cd-gpios = <&pio 10 0>;
     status = "okay";
     vmmc-supply = <&mt_pmic_vmch_ldo_reg>;
 };

&mmc1_pins_default {
	pins_insert {
		pinmux = <PINMUX_GPIO10__FUNC_GPIO10>;
	};
};

&mt6360_ldo {
    sdcard_det_en = <1>;
    sdcard_hlact = <0>;
};
// 1 = ldo power, refer to oplus_fp_common.h

//#ifdef OPLUS_VENDOR_SWTP
&swtp {
    compatible = "mediatek, swtp-eint";
    debounce = <512000>;
};

&u2port0 {
	mediatek,eye-vrt = <7>; /* 0~7 */
	mediatek,eye-term = <5>; /* 0~7 */
	mediatek,eye-rev6 = <3>; /* 0~3 */
	mediatek,eye-disc = <7>; /* 0~8 */
	mediatek,host-eye-vrt = <6>; /* 0~7 */
	mediatek,host-eye-term = <3>; /* 0~7 */
	mediatek,host-eye-rev6 = <3>; /* 0~3 */
	mediatek,host-eye-disc = <0xf>; /* 0~8 */
};
&extcon_usb {
	vbus-current = <1300000>;
};

&mt_pmic_vemc_ldo_reg {
	regulator-min-microvolt = <2500000>;
	regulator-max-microvolt = <2500000>;
};

//#endif  /*OPLUS_VENDOR_SWTP*/
#include <oplus6877_23689/cust.dtsi>
//#include "mediatek/cust_mt6877_22612_charge.dtsi"
//#include "mediatek/cust_mt6877_22710_charge.dtsi"
#include "mediatek/cust_mt6877_23689_charge.dtsi"
/*#include "mediatek/cust_mt6877_touch_1080x2300.dtsi"*/
#include "mediatek/cust_mt6877_camera_23689.dtsi"
//#include "mediatek/nfc/mt6877_roma_st54h.dtsi"
/*End of this file, DO NOT ADD ANYTHING HERE*/

